# STM32L0x1 register map
File version: 1.6
CPU: CM0+ r0p0, little endian, MPU, no FPU, 2 interrupt priority bits
Registers are 32-bit, read-write, reset 0x0 unless marked. A register's access mark holds for its fields unless they carry their own. Offsets are from the block's base; [hi:lo] are bit positions; {n}, {i} and the like mark numbered series.

## GPIOA — General-purpose I/Os
Base 0x50000000
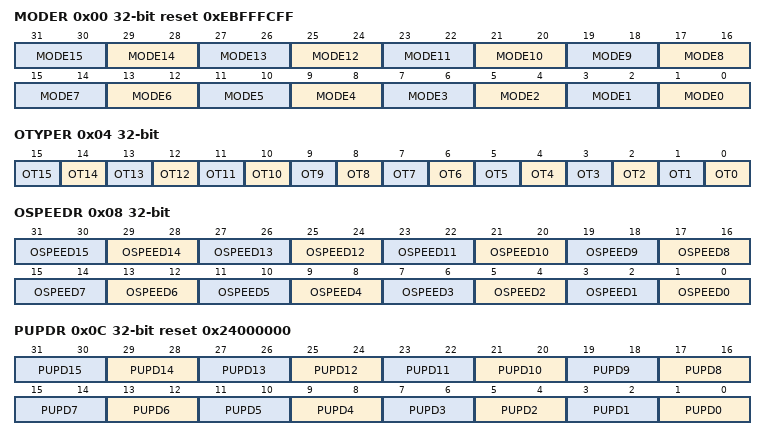
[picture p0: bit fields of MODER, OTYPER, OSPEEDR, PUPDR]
0x00 MODER reset 0xEBFFFCFF — GPIO port mode register
  [2n+1:2n] MODE{n} (n=0..15) — Port x configuration pin {n}
    0=Input mode; 1=Output (General purpose output mode); 2=Alternate function mode; 3=Analog mode
0x04 OTYPER — GPIO port output type register
  [n] OT{n} (n=0..15) — Port x configuration pin {n}
    0=PushPull (Output push-pull (reset state)); 1=OpenDrain (Output open-drain)
0x08 OSPEEDR — GPIO port output speed register
  [2n+1:2n] OSPEED{n} (n=0..15) — Port x configuration pin {n}
    0=LowSpeed; 1=MediumSpeed; 2=HighSpeed; 3=VeryHighSpeed
0x0C PUPDR reset 0x24000000 — GPIO port pull-up/pull-down register
  [2n+1:2n] PUPD{n} (n=0..15) — Port x configuration pin {n}
    0=Floating (No pull-up, pull-down); 1=PullUp; 2=PullDown
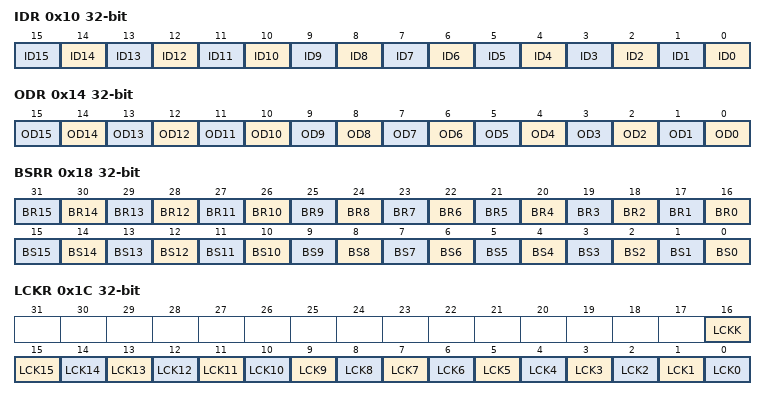
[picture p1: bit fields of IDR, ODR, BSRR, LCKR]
0x10 IDR ro — GPIO port input data register
  [n] ID{n} (n=0..15) — Port input data pin {n}
    0=Low (Input is logic low); 1=High (Input is logic high)
0x14 ODR — GPIO port output data register
  [n] OD{n} (n=0..15) — Port output data pin {n}
    0=Low (Set output to logic low); 1=High (Set output to logic high)
0x18 BSRR wo — GPIO port bit set/reset register
  [n+16] BR{n} (n=0..15) — Port x reset pin {n}
    1=Resets the corresponding ODx bit
  [n] BS{n} (n=0..15) — Port x set pin {n}
    1=Set (Sets the corresponding ODx bit)
0x1C LCKR — GPIO port configuration lock register
  [16] LCKK — Port x lock bit y (y= 0..15)
    0=NotActive (Port configuration lock key not active); 1=Active (Port configuration lock key active)
  [n] LCK{n} (n=0..15) — Port x lock pin {n}
    0=Unlocked (Port configuration not locked); 1=Locked (Port configuration locked)
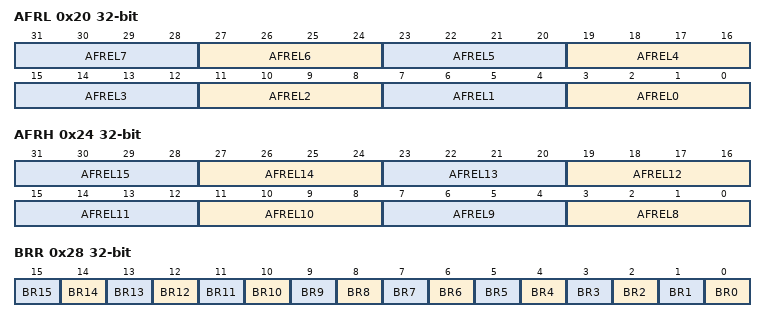
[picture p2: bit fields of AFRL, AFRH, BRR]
0x20 AFRL — GPIO alternate function low register
  [3:0] AFR{x} (x=EL0,EL1,EL2,EL3,EL4,EL5,EL6,EL7; step 4) — Alternate function selection for port x pin y (y = 0..7)
    {v}=AF{v} (v=0..7)
0x24 AFRH — GPIO alternate function high register
  [3:0] AFR{x} (x=EL8,EL9,EL10,EL11,EL12,EL13,EL14,EL15; step 4) — Alternate function selection for port x pin y (y = 8..15)
    {v}=AF{v} (v=0..7)
0x28 BRR wo — GPIO port bit reset register
  [n] BR{n} (n=0..15) — Port x reset pin {n}
    0=No action on the corresponding ODx bit; 1=Reset the ODx bit

## GPIOB — General-purpose I/Os
Base 0x50000400
Same registers: GPIOC 0x50000800, GPIOD 0x50000C00, GPIOE 0x50001000, GPIOH 0x50001C00
Registers as GPIOA; these are added or differ:
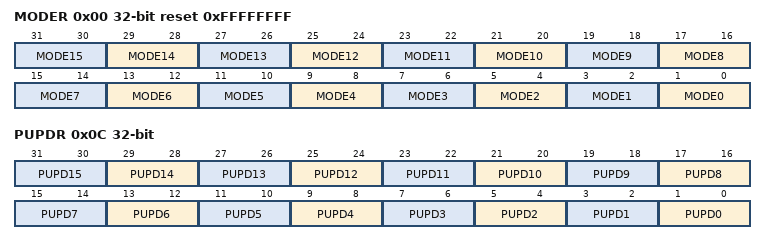
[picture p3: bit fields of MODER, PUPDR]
0x00 MODER reset 0xFFFFFFFF — GPIO port mode register
  [2n+1:2n] MODE{n} (n=0..15) — Port x configuration pin {n}
    0=Input mode; 1=Output (General purpose output mode); 2=Alternate function mode; 3=Analog mode
0x0C PUPDR — GPIO port pull-up/pull-down register
  [2n+1:2n] PUPD{n} (n=0..15) — Port x configuration pin {n}
    0=Floating (No pull-up, pull-down); 1=PullUp; 2=PullDown

## IWDG — Independent watchdog
Base 0x40003000
0x00 KR wo — Key register
  [15:0] KEY — Key value (write only, read 0x0000)
    0x5555=Unlock (Enable access to PR, RLR and WINR registers); 0xAAAA=Feed watchdog with RLR register value; 0xCCCC=Start the watchdog
0x04 PR — Prescaler register
  [2:0] PR — Prescaler divider
    0=DivideBy4 (Divider /4); 1=DivideBy8 (Divider /8); 2=DivideBy16 (Divider /16); 3=DivideBy32 (Divider /32); 4=DivideBy64 (Divider /64); 5=DivideBy128 (Divider /128); other=DivideBy256 (Divider /256)
0x08 RLR reset 0xFFF — Reload register
  [11:0] RL — Watchdog counter reload value
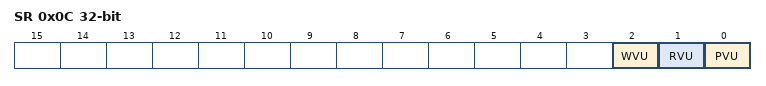
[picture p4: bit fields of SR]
0x0C SR ro — Status register
  [2] WVU — Watchdog counter window value update
  [1] RVU — Watchdog counter reload value update
  [0] PVU — Watchdog prescaler value update
0x10 WINR reset 0xFFF — Window register
  [11:0] WIN — Watchdog counter window value
